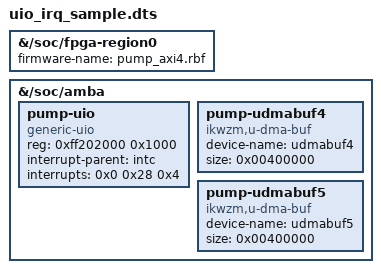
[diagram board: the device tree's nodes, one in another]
/dts-v1/;/plugin/;
/ {
	fragment@0 {
		target-path = "/soc/fpga-region0";
		__overlay__ {
			firmware-name = "pump_axi4.rbf";
		};
	};
	fragment@1 {
		target-path = "/soc/amba";
		#address-cells = <0x1>;
		#size-cells = <0x1>;
		__overlay__ {
			#address-cells = <0x1>;
			#size-cells = <0x1>;

			pump-uio {
				compatible = "generic-uio";
				reg = <0xff202000 0x1000>;
				interrupt-parent = <&intc>;
				interrupts = <0x0 0x28 0x4>;
	                };

			pump-udmabuf4 {
				compatible  = "ikwzm,u-dma-buf";
				device-name = "udmabuf4";
				size = <0x00400000>;
	                };

			pump-udmabuf5 {
				compatible = "ikwzm,u-dma-buf";
				device-name = "udmabuf5";
				size = <0x00400000>;
			};
                };
	} ;
} ;
